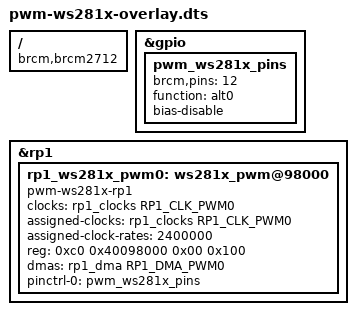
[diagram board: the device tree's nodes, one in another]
/dts-v1/;
/plugin/;

#include <dt-bindings/clock/rp1.h>
#include <dt-bindings/mfd/rp1.h>

/ {
    compatible = "brcm,brcm2712";

    fragment@0 {
        target = <&gpio>;

        __overlay__ {
            pwm_ws281x_pins: pwm_ws281x_pins {
                brcm,pins = <12>;
                function = "alt0";
                bias-disable;
            };
        };
    };

    fragment@1 {
        target = <&rp1>;

        __overlay__ {
            #address-cells = <2>;
            #size-cells = <2>;

            rp1_ws281x_pwm0: ws281x_pwm@98000 {
                compatible = "pwm-ws281x-rp1";
                clocks = <&rp1_clocks RP1_CLK_PWM0>;
                assigned-clocks = <&rp1_clocks RP1_CLK_PWM0>;
                assigned-clock-rates = <2400000>;
                reg = <0xc0 0x40098000 0x00 0x100>;
                #pwm-cells = <0x03>;
                dmas = <&rp1_dma RP1_DMA_PWM0>;
                dma-names = "pwm0";
                pinctrl-names = "default";
                pinctrl-0 = <&pwm_ws281x_pins>;
                status = "okay";
            };
        };
    };

    __overrides__ {
        pin  = <&pwm_ws281x_pins>,"brcm,pins:0";
        func = <&pwm_ws281x_pins>,"function";
    };
};
